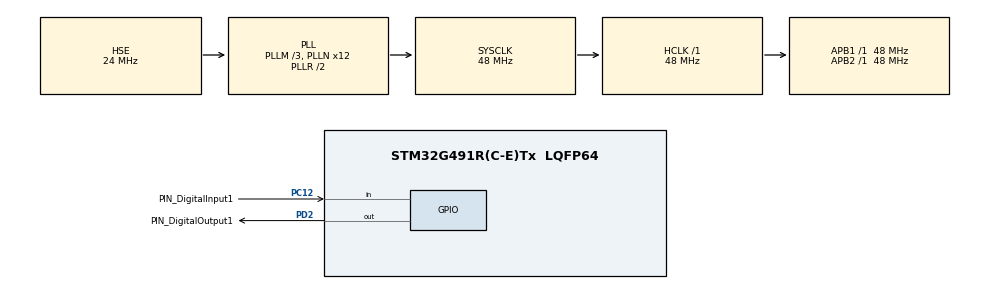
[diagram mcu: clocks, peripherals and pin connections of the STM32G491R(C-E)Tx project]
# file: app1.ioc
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FREERTOS.Tasks01=MainAppTask,40,4096,vMainAppTask,Default,NULL,Static,MainAppTaskBuffer,MainAppTaskControlBlock
FREERTOS.configENABLE_BACKWARD_COMPATIBILITY=0
FREERTOS.configGENERATE_RUN_TIME_STATS=1
FREERTOS.configRECORD_STACK_HIGH_ADDRESS=1
FREERTOS.configTIMER_QUEUE_LENGTH=32
FREERTOS.configTIMER_TASK_PRIORITY=16
FREERTOS.configTIMER_TASK_STACK_DEPTH=512
FREERTOS.configUSE_OS2_THREAD_ENUMERATE=0
FREERTOS.configUSE_TRACE_FACILITY=0
Mcu.Family=STM32G4
Mcu.Name=STM32G491R(C-E)Tx
Mcu.Package=LQFP64
NVIC.PriorityGroup=NVIC_PRIORITYGROUP_4
NVIC.TIM6_DAC_IRQn=true\:15\:0\:false\:false\:true\:false\:false\:true\:true
NVIC.TimeBase=TIM6_DAC_IRQn
NVIC.TimeBaseIP=TIM6
PA13.Mode=JTAG_5_pins
PA13.Signal=SYS_JTMS-SWDIO
PA14.Mode=JTAG_5_pins
PA14.Signal=SYS_JTCK-SWCLK
PA15.Mode=JTAG_5_pins
PA15.Signal=SYS_JTDI
PB3.Mode=JTAG_5_pins
PB3.Signal=SYS_JTDO-SWO
PB4.Mode=JTAG_5_pins
PB4.Signal=SYS_JTRST
PC12.GPIO_Label=PIN_DigitalInput1
PC12.Signal=GPIO_Input
PD2.GPIO_Label=PIN_DigitalOutput1
PD2.Signal=GPIO_Output
PF0-OSC_IN.Mode=HSE-External-Oscillator
PF0-OSC_IN.Signal=RCC_OSC_IN
PF1-OSC_OUT.Mode=HSE-External-Oscillator
PF1-OSC_OUT.Signal=RCC_OSC_OUT
ProjectManager.HeapSize=0x200
ProjectManager.StackSize=0x400
ProjectManager.TargetToolchain=CMake
RCC.ADC12Freq_Value=48000000
RCC.ADC345Freq_Value=48000000
RCC.AHBFreq_Value=48000000
RCC.APB1Freq_Value=48000000
RCC.APB1TimFreq_Value=48000000
RCC.APB2Freq_Value=48000000
RCC.APB2TimFreq_Value=48000000
RCC.CortexFreq_Value=48000000
RCC.EXTERNAL_CLOCK_VALUE=12288000
RCC.HCLKFreq_Value=48000000
RCC.HSE_VALUE=24000000
RCC.HSI48_VALUE=48000000
RCC.HSI_VALUE=16000000
RCC.LSE_VALUE=32768
RCC.PLLM=RCC_PLLM_DIV3
RCC.PLLN=12
RCC.PLLSourceVirtual=RCC_PLLSOURCE_HSE
RCC.SYSCLKFreq_VALUE=48000000
RCC.SYSCLKSource=RCC_SYSCLKSOURCE_PLLCLK
RCC.USBFreq_Value=48000000
RCC.VCOOutputFreq_Value=96000000
VP_FREERTOS_VS_CMSIS_V2.Mode=CMSIS_V2
VP_SYS_VS_DBSignals.Mode=DisableDeadBatterySignals
VP_SYS_VS_tim6.Mode=TIM6
board=custom

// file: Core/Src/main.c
/* USER CODE BEGIN Header */
/**
  ******************************************************************************
  * @file           : main.c
  * @brief          : Main program body
  ******************************************************************************
  * @attention
  *
  * Copyright (c) 2025 STMicroelectronics.
  * All rights reserved.
  *
  * This software is licensed under terms that can be found in the LICENSE file
  * in the root directory of this software component.
  * If no LICENSE file comes with this software, it is provided AS-IS.
  *
  ******************************************************************************
  */
/* USER CODE END Header */
#include "main.h"
#include "cmsis_os.h"
#include "gpio.h"

void SystemClock_Config(void);
void MX_FREERTOS_Init(void);

int main(void)
{

  /* MCU Configuration--------------------------------------------------------*/

  /* Reset of all peripherals, Initializes the Flash interface and the Systick. */
  HAL_Init();

  /* Configure the system clock */
  SystemClock_Config();

  /* Initialize all configured peripherals */
  MX_GPIO_Init();

  /* Init scheduler */
  osKernelInitialize();  /* Call init function for freertos objects (in cmsis_os2.c) */
  MX_FREERTOS_Init();

  /* Start scheduler */
  osKernelStart();

  /* We should never get here as control is now taken by the scheduler */

  /* Infinite loop */
  while (1)
  {

  }
}

void SystemClock_Config(void)
{
  RCC_OscInitTypeDef RCC_OscInitStruct = {0};
  RCC_ClkInitTypeDef RCC_ClkInitStruct = {0};

  /** Configure the main internal regulator output voltage
  */
  HAL_PWREx_ControlVoltageScaling(PWR_REGULATOR_VOLTAGE_SCALE1);

  /** Initializes the RCC Oscillators according to the specified parameters
  * in the RCC_OscInitTypeDef structure.
  */
  RCC_OscInitStruct.OscillatorType = RCC_OSCILLATORTYPE_HSE;
  RCC_OscInitStruct.HSEState = RCC_HSE_ON;
  RCC_OscInitStruct.PLL.PLLState = RCC_PLL_ON;
  RCC_OscInitStruct.PLL.PLLSource = RCC_PLLSOURCE_HSE;
  RCC_OscInitStruct.PLL.PLLM = RCC_PLLM_DIV3;
  RCC_OscInitStruct.PLL.PLLN = 12;
  RCC_OscInitStruct.PLL.PLLP = RCC_PLLP_DIV2;
  RCC_OscInitStruct.PLL.PLLQ = RCC_PLLQ_DIV2;
  RCC_OscInitStruct.PLL.PLLR = RCC_PLLR_DIV2;
  if (HAL_RCC_OscConfig(&RCC_OscInitStruct) != HAL_OK)
  {
    Error_Handler();
  }

  /** Initializes the CPU, AHB and APB buses clocks
  */
  RCC_ClkInitStruct.ClockType = RCC_CLOCKTYPE_HCLK|RCC_CLOCKTYPE_SYSCLK
                              |RCC_CLOCKTYPE_PCLK1|RCC_CLOCKTYPE_PCLK2;
  RCC_ClkInitStruct.SYSCLKSource = RCC_SYSCLKSOURCE_PLLCLK;
  RCC_ClkInitStruct.AHBCLKDivider = RCC_SYSCLK_DIV1;
  RCC_ClkInitStruct.APB1CLKDivider = RCC_HCLK_DIV1;
  RCC_ClkInitStruct.APB2CLKDivider = RCC_HCLK_DIV1;

  if (HAL_RCC_ClockConfig(&RCC_ClkInitStruct, FLASH_LATENCY_1) != HAL_OK)
  {
    Error_Handler();
  }
}

void HAL_TIM_PeriodElapsedCallback(TIM_HandleTypeDef *htim)
{
  if (htim->Instance == TIM6)
  {
    HAL_IncTick();
  }
}

void Error_Handler(void)
{
  __disable_irq();
  while (1)
  {
  }
}

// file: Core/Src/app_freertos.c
/* USER CODE BEGIN Header */
/**
  ******************************************************************************
  * File Name          : app_freertos.c
  * Description        : Code for freertos applications
  ******************************************************************************
  * @attention
  *
  * Copyright (c) 2026 STMicroelectronics.
  * All rights reserved.
  *
  * This software is licensed under terms that can be found in the LICENSE file
  * in the root directory of this software component.
  * If no LICENSE file comes with this software, it is provided AS-IS.
  *
  ******************************************************************************
  */
/* USER CODE END Header */

#include "FreeRTOS.h"
#include "task.h"
#include "main.h"
#include "cmsis_os.h"

/* USER CODE BEGIN Includes */
#include <src/app1Main.h>
/* USER CODE END Includes */

typedef StaticTask_t osStaticThreadDef_t;

/* Definitions for MainAppTask */
osThreadId_t MainAppTaskHandle;
uint32_t MainAppTaskBuffer[ 4096 ];
osStaticThreadDef_t MainAppTaskControlBlock;
const osThreadAttr_t MainAppTask_attributes = {
  .name = "MainAppTask",
  .stack_mem = &MainAppTaskBuffer[0],
  .stack_size = sizeof(MainAppTaskBuffer),
  .cb_mem = &MainAppTaskControlBlock,
  .cb_size = sizeof(MainAppTaskControlBlock),
  .priority = (osPriority_t) osPriorityHigh,
};

void vMainAppTask(void *argument);

void MX_FREERTOS_Init(void); /* (MISRA C 2004 rule 8.1) */

/* Hook prototypes */
void configureTimerForRunTimeStats(void);
unsigned long getRunTimeCounterValue(void);

/* USER CODE BEGIN 1 */
/* Functions needed when configGENERATE_RUN_TIME_STATS is on */
__weak void configureTimerForRunTimeStats(void)
{

}

__weak unsigned long getRunTimeCounterValue(void)
{
return 0;
}
/* USER CODE END 1 */

void MX_FREERTOS_Init(void) {

  /* Create the thread(s) */
  /* creation of MainAppTask */
  MainAppTaskHandle = osThreadNew(vMainAppTask, NULL, &MainAppTask_attributes);

}

void vMainAppTask(void *argument)
{
  /* USER CODE BEGIN vMainAppTask */
  UNUSED(argument);

  /* Infinite loop */
  app1MainWrapper();
  /* USER CODE END vMainAppTask */
}

/* USER CODE BEGIN Application */
void APP_setMainTaskPriorityLow()
{
  const osStatus_t status = osThreadSetPriority(MainAppTaskHandle, osPriorityLow);
  UNUSED(status);
}

void APP_taskDelayMs(const uint32_t delayMs)
{
  const osStatus_t status = osDelay(pdMS_TO_TICKS(delayMs));
  UNUSED(status);
}
/* USER CODE END Application */
